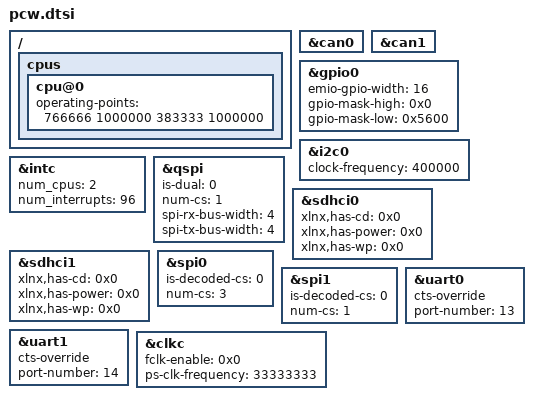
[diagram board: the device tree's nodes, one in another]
/*
 * CAUTION: This file is automatically generated by Xilinx.
 * Version: XSCT 2018.3
 * Today is: Thu Jun 18 10:42:37 2020
 */


/ {
	cpus {
		cpu@0 {
			operating-points = <766666 1000000 383333 1000000>;
		};
	};
};
&can0 {
	status = "okay";
};
&can1 {
	status = "okay";
};
&gpio0 {
	emio-gpio-width = <16>;
	gpio-mask-high = <0x0>;
	gpio-mask-low = <0x5600>;
};
&i2c0 {
	clock-frequency = <400000>;
	status = "okay";
};
&intc {
	num_cpus = <2>;
	num_interrupts = <96>;
};
&qspi {
	is-dual = <0>;
	num-cs = <1>;
	spi-rx-bus-width = <4>;
	spi-tx-bus-width = <4>;
	status = "okay";
};
&sdhci0 {
	status = "okay";
	xlnx,has-cd = <0x0>;
	xlnx,has-power = <0x0>;
	xlnx,has-wp = <0x0>;
};
&sdhci1 {
	status = "okay";
	xlnx,has-cd = <0x0>;
	xlnx,has-power = <0x0>;
	xlnx,has-wp = <0x0>;
};
&spi0 {
	is-decoded-cs = <0>;
	num-cs = <3>;
	status = "okay";
};
&spi1 {
	is-decoded-cs = <0>;
	num-cs = <1>;
	status = "okay";
};
&uart0 {
	cts-override ;
	device_type = "serial";
	port-number = <13>;
	status = "okay";
};
&uart1 {
	cts-override ;
	device_type = "serial";
	port-number = <14>;
	status = "okay";
};
&clkc {
	fclk-enable = <0x0>;
	ps-clk-frequency = <33333333>;
};
